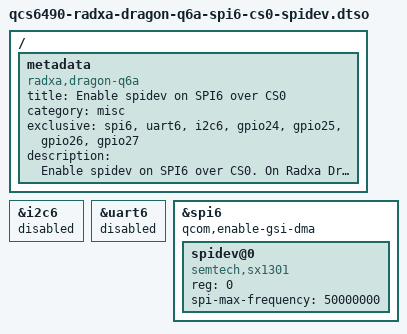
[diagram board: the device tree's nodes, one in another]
// SPDX-License-Identifier: BSD-3-Clause
/*
 * Copyright (c) 2025 Radxa Computer (Shenzhen) Co., Ltd.
 */

/dts-v1/;
/plugin/;

/ {
    metadata {
        title = "Enable spidev on SPI6 over CS0";
        compatible = "radxa,dragon-q6a";
        category = "misc";
        exclusive = "spi6", "uart6", "i2c6", "gpio24", "gpio25", "gpio26", "gpio27";
        description = "Enable spidev on SPI6 over CS0. 
On Radxa Dragon Q6A, this is pin 3(miso), 5(mosi), 16(sclk), 18(cs0).";
    };
};

&i2c6 {
	status = "disabled";
};

&uart6 {
	status = "disabled";
};

&spi6 {
	qcom,enable-gsi-dma;
	status = "okay";
	
	spidev@0 {
		compatible = "semtech,sx1301";
		status = "okay";
		reg = <0>;
		spi-max-frequency = <50000000>;
	};
};
